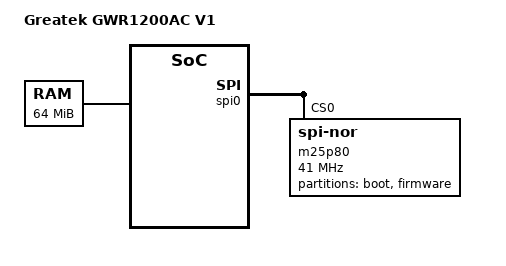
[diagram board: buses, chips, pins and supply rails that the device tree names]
// SPDX-License-Identifier: GPL-2.0
/dts-v1/;

#include "RTL8197F.dtsi"

/ {
	compatible = "greatek,gwr1200ac", "realtek,rtl8197f-soc";
	model = "Greatek GWR1200AC V1";

	memory {
		device_type = "memory";
		reg = <0x0 0x4000000>;
	};

	chosen {
		bootargs = "console=ttyS0,38400";
	};
};

&spi0 {
	status = "okay";

	m25p80@0 {
		#address-cells = <1>;
		#size-cells = <1>;
		compatible = "jedec,spi-nor";
		reg = <0>;
		spi-max-frequency = <41000000>;

		partition@0 {
			label = "boot";
			reg = <0x0 0x30000>;
			read-only;
		};

		partition@30000 {
			label = "firmware";
			reg = <0x30000 0x7C0000>;
		};
	};
};
